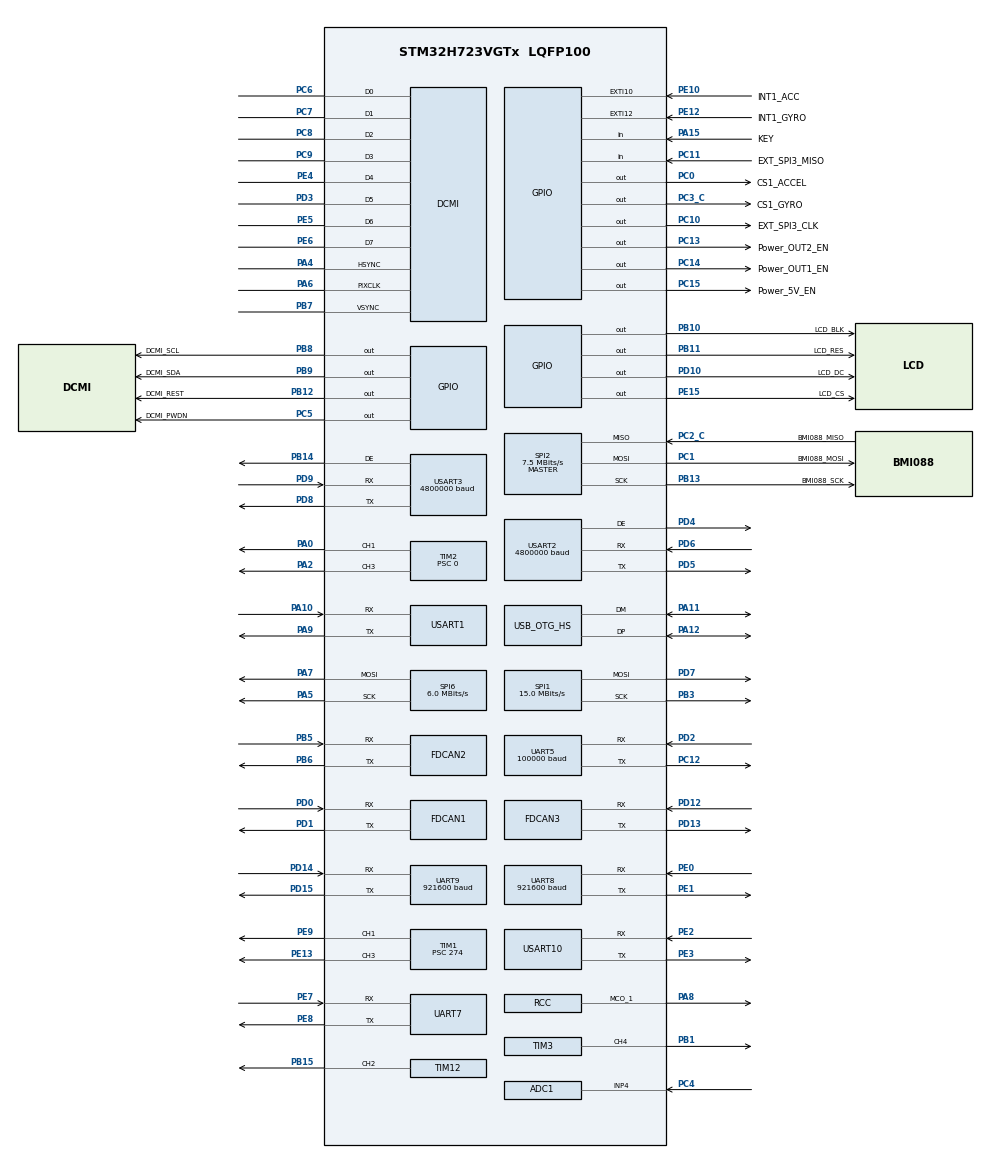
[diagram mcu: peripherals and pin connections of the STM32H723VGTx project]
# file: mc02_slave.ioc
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ADC1.Channel-0\#ChannelRegularConversion=ADC_CHANNEL_4
ADC1.ClockPrescaler=ADC_CLOCK_ASYNC_DIV128
ADC1.ContinuousConvMode=ENABLE
ADC1.ConversionDataManagement=ADC_CONVERSIONDATA_DMA_CIRCULAR
ADC1.NbrOfConversionFlag=1
ADC1.OffsetNumber-0\#ChannelRegularConversion=ADC_OFFSET_NONE
ADC1.OffsetSignedSaturation-0\#ChannelRegularConversion=DISABLE
ADC1.Rank-0\#ChannelRegularConversion=1
ADC1.SamplingTime-0\#ChannelRegularConversion=ADC_SAMPLETIME_64CYCLES_5
ADC1.master=1
Bdma.Request0=SPI6_TX
Bdma.RequestsNb=1
Bdma.SPI6_TX.0.Direction=DMA_MEMORY_TO_PERIPH
Bdma.SPI6_TX.0.EventEnable=DISABLE
Bdma.SPI6_TX.0.Instance=BDMA_Channel0
Bdma.SPI6_TX.0.MemDataAlignment=DMA_MDATAALIGN_BYTE
Bdma.SPI6_TX.0.MemInc=DMA_MINC_ENABLE
Bdma.SPI6_TX.0.Mode=DMA_NORMAL
Bdma.SPI6_TX.0.PeriphDataAlignment=DMA_PDATAALIGN_BYTE
Bdma.SPI6_TX.0.PeriphInc=DMA_PINC_DISABLE
Bdma.SPI6_TX.0.Polarity=HAL_DMAMUX_REQ_GEN_RISING
Bdma.SPI6_TX.0.Priority=DMA_PRIORITY_LOW
Bdma.SPI6_TX.0.RequestNumber=1
Bdma.SPI6_TX.0.SignalID=NONE
Bdma.SPI6_TX.0.SyncEnable=DISABLE
Bdma.SPI6_TX.0.SyncPolarity=HAL_DMAMUX_SYNC_NO_EVENT
Bdma.SPI6_TX.0.SyncRequestNumber=1
Bdma.SPI6_TX.0.SyncSignalID=NONE
CORTEX_M7.AccessPermission_Spec=MPU_REGION_FULL_ACCESS
CORTEX_M7.BaseAddress_Spec=0x24000000
CORTEX_M7.CPU_DCache=Enabled
CORTEX_M7.CPU_ICache=Enabled
CORTEX_M7.DisableExec_Spec=MPU_INSTRUCTION_ACCESS_ENABLE
CORTEX_M7.Enable_S-Cortex_Memory_Protection_Unit_Region1_Settings_S=__NULL
CORTEX_M7.Enable_S-Cortex_Memory_Protection_Unit_Region2_Settings_S=__NULL
CORTEX_M7.IsShareable_Spec=MPU_ACCESS_NOT_SHAREABLE
CORTEX_M7.MPU_Control=MPU_HFNMI_PRIVDEF
CORTEX_M7.Size_Spec=MPU_REGION_SIZE_32KB
CORTEX_M7.SubRegionDisable_Spec=0x00
CORTEX_M7.TypeExtField_Spec=MPU_TEX_LEVEL1
CORTEX_M7.default_mode_Activation=1
DCMI.JPEGMode=DCMI_JPEG_DISABLE
DCMI.PCKPolarity=DCMI_PCKPOLARITY_RISING
DCMI.VSPolarity=DCMI_VSPOLARITY_LOW
Dma.ADC1.13.Direction=DMA_PERIPH_TO_MEMORY
Dma.ADC1.13.EventEnable=DISABLE
Dma.ADC1.13.FIFOMode=DMA_FIFOMODE_DISABLE
Dma.ADC1.13.Instance=DMA2_Stream5
Dma.ADC1.13.MemDataAlignment=DMA_MDATAALIGN_HALFWORD
Dma.ADC1.13.MemInc=DMA_MINC_ENABLE
Dma.ADC1.13.Mode=DMA_CIRCULAR
Dma.ADC1.13.PeriphDataAlignment=DMA_PDATAALIGN_HALFWORD
Dma.ADC1.13.PeriphInc=DMA_PINC_DISABLE
Dma.ADC1.13.Polarity=HAL_DMAMUX_REQ_GEN_RISING
Dma.ADC1.13.Priority=DMA_PRIORITY_LOW
Dma.ADC1.13.RequestNumber=1
Dma.ADC1.13.SignalID=NONE
Dma.ADC1.13.SyncEnable=DISABLE
Dma.ADC1.13.SyncPolarity=HAL_DMAMUX_SYNC_NO_EVENT
Dma.ADC1.13.SyncRequestNumber=1
Dma.ADC1.13.SyncSignalID=NONE
Dma.Request0=USART10_RX
Dma.Request1=USART10_TX
Dma.Request10=USART2_TX
Dma.Request11=USART3_RX
Dma.Request12=USART3_TX
Dma.Request13=ADC1
Dma.Request2=UART7_RX
Dma.Request3=UART7_TX
Dma.Request4=USART1_RX
Dma.Request5=USART1_TX
Dma.Request6=UART5_RX
Dma.Request7=SPI2_RX
Dma.Request8=SPI2_TX
Dma.Request9=USART2_RX
Dma.SPI2_RX.7.Direction=DMA_PERIPH_TO_MEMORY
Dma.SPI2_RX.7.EventEnable=DISABLE
Dma.SPI2_RX.7.FIFOMode=DMA_FIFOMODE_DISABLE
Dma.SPI2_RX.7.Instance=DMA2_Stream0
Dma.SPI2_RX.7.MemDataAlignment=DMA_MDATAALIGN_BYTE
Dma.SPI2_RX.7.MemInc=DMA_MINC_ENABLE
Dma.SPI2_RX.7.Mode=DMA_NORMAL
Dma.SPI2_RX.7.PeriphDataAlignment=DMA_PDATAALIGN_BYTE
Dma.SPI2_RX.7.PeriphInc=DMA_PINC_DISABLE
Dma.SPI2_RX.7.Polarity=HAL_DMAMUX_REQ_GEN_RISING
Dma.SPI2_RX.7.Priority=DMA_PRIORITY_LOW
Dma.SPI2_RX.7.RequestNumber=1
Dma.SPI2_RX.7.SignalID=NONE
Dma.SPI2_RX.7.SyncEnable=DISABLE
Dma.SPI2_RX.7.SyncPolarity=HAL_DMAMUX_SYNC_NO_EVENT
Dma.SPI2_RX.7.SyncRequestNumber=1
Dma.SPI2_RX.7.SyncSignalID=NONE
Dma.SPI2_TX.8.Direction=DMA_MEMORY_TO_PERIPH
Dma.SPI2_TX.8.EventEnable=DISABLE
Dma.SPI2_TX.8.FIFOMode=DMA_FIFOMODE_DISABLE
Dma.SPI2_TX.8.Instance=DMA2_Stream1
Dma.SPI2_TX.8.MemDataAlignment=DMA_MDATAALIGN_BYTE
Dma.SPI2_TX.8.MemInc=DMA_MINC_ENABLE
Dma.SPI2_TX.8.Mode=DMA_NORMAL
Dma.SPI2_TX.8.PeriphDataAlignment=DMA_PDATAALIGN_BYTE
Dma.SPI2_TX.8.PeriphInc=DMA_PINC_DISABLE
Dma.SPI2_TX.8.Polarity=HAL_DMAMUX_REQ_GEN_RISING
Dma.SPI2_TX.8.Priority=DMA_PRIORITY_LOW
Dma.SPI2_TX.8.RequestNumber=1
Dma.SPI2_TX.8.SignalID=NONE
Dma.SPI2_TX.8.SyncEnable=DISABLE
Dma.SPI2_TX.8.SyncPolarity=HAL_DMAMUX_SYNC_NO_EVENT
Dma.SPI2_TX.8.SyncRequestNumber=1
Dma.SPI2_TX.8.SyncSignalID=NONE
Dma.UART5_RX.6.Direction=DMA_PERIPH_TO_MEMORY
Dma.UART5_RX.6.EventEnable=DISABLE
Dma.UART5_RX.6.FIFOMode=DMA_FIFOMODE_DISABLE
Dma.UART5_RX.6.Instance=DMA1_Stream0
Dma.UART5_RX.6.MemDataAlignment=DMA_MDATAALIGN_BYTE
Dma.UART5_RX.6.MemInc=DMA_MINC_ENABLE
Dma.UART5_RX.6.Mode=DMA_CIRCULAR
Dma.UART5_RX.6.PeriphDataAlignment=DMA_PDATAALIGN_BYTE
Dma.UART5_RX.6.PeriphInc=DMA_PINC_DISABLE
Dma.UART5_RX.6.Polarity=HAL_DMAMUX_REQ_GEN_RISING
Dma.UART5_RX.6.Priority=DMA_PRIORITY_HIGH
Dma.UART5_RX.6.RequestNumber=1
Dma.UART5_RX.6.SignalID=NONE
Dma.UART5_RX.6.SyncEnable=DISABLE
Dma.UART5_RX.6.SyncPolarity=HAL_DMAMUX_SYNC_NO_EVENT
Dma.UART5_RX.6.SyncRequestNumber=1
Dma.UART5_RX.6.SyncSignalID=NONE
Dma.UART7_RX.2.Direction=DMA_PERIPH_TO_MEMORY
Dma.UART7_RX.2.EventEnable=DISABLE
Dma.UART7_RX.2.FIFOMode=DMA_FIFOMODE_DISABLE
Dma.UART7_RX.2.Instance=DMA1_Stream3
Dma.UART7_RX.2.MemDataAlignment=DMA_MDATAALIGN_BYTE
Dma.UART7_RX.2.MemInc=DMA_MINC_ENABLE
Dma.UART7_RX.2.Mode=DMA_CIRCULAR
Dma.UART7_RX.2.PeriphDataAlignment=DMA_PDATAALIGN_BYTE
Dma.UART7_RX.2.PeriphInc=DMA_PINC_DISABLE
Dma.UART7_RX.2.Polarity=HAL_DMAMUX_REQ_GEN_RISING
Dma.UART7_RX.2.Priority=DMA_PRIORITY_HIGH
Dma.UART7_RX.2.RequestNumber=1
Dma.UART7_RX.2.SignalID=NONE
Dma.UART7_RX.2.SyncEnable=DISABLE
Dma.UART7_RX.2.SyncPolarity=HAL_DMAMUX_SYNC_NO_EVENT
Dma.UART7_RX.2.SyncRequestNumber=1
Dma.UART7_RX.2.SyncSignalID=NONE
Dma.UART7_TX.3.Direction=DMA_MEMORY_TO_PERIPH
Dma.UART7_TX.3.EventEnable=DISABLE
Dma.UART7_TX.3.FIFOMode=DMA_FIFOMODE_DISABLE
Dma.UART7_TX.3.Instance=DMA1_Stream4
Dma.UART7_TX.3.MemDataAlignment=DMA_MDATAALIGN_BYTE
Dma.UART7_TX.3.MemInc=DMA_MINC_ENABLE
Dma.UART7_TX.3.Mode=DMA_NORMAL
Dma.UART7_TX.3.PeriphDataAlignment=DMA_PDATAALIGN_BYTE
Dma.UART7_TX.3.PeriphInc=DMA_PINC_DISABLE
Dma.UART7_TX.3.Polarity=HAL_DMAMUX_REQ_GEN_RISING
Dma.UART7_TX.3.Priority=DMA_PRIORITY_LOW
Dma.UART7_TX.3.RequestNumber=1
Dma.UART7_TX.3.SignalID=NONE
Dma.UART7_TX.3.SyncEnable=DISABLE
Dma.UART7_TX.3.SyncPolarity=HAL_DMAMUX_SYNC_NO_EVENT
Dma.UART7_TX.3.SyncRequestNumber=1
Dma.UART7_TX.3.SyncSignalID=NONE
Dma.USART10_RX.0.Direction=DMA_PERIPH_TO_MEMORY
Dma.USART10_RX.0.EventEnable=DISABLE
Dma.USART10_RX.0.FIFOMode=DMA_FIFOMODE_DISABLE
Dma.USART10_RX.0.Instance=DMA1_Stream1
Dma.USART10_RX.0.MemDataAlignment=DMA_MDATAALIGN_BYTE
Dma.USART10_RX.0.MemInc=DMA_MINC_ENABLE
Dma.USART10_RX.0.Mode=DMA_CIRCULAR
Dma.USART10_RX.0.PeriphDataAlignment=DMA_PDATAALIGN_BYTE
Dma.USART10_RX.0.PeriphInc=DMA_PINC_DISABLE
Dma.USART10_RX.0.Polarity=HAL_DMAMUX_REQ_GEN_RISING
Dma.USART10_RX.0.Priority=DMA_PRIORITY_HIGH
Dma.USART10_RX.0.RequestNumber=1
Dma.USART10_RX.0.SignalID=NONE
Dma.USART10_RX.0.SyncEnable=DISABLE
Dma.USART10_RX.0.SyncPolarity=HAL_DMAMUX_SYNC_NO_EVENT
Dma.USART10_RX.0.SyncRequestNumber=1
Dma.USART10_RX.0.SyncSignalID=NONE
Dma.USART10_TX.1.Direction=DMA_MEMORY_TO_PERIPH
Dma.USART10_TX.1.EventEnable=DISABLE
Dma.USART10_TX.1.FIFOMode=DMA_FIFOMODE_DISABLE
Dma.USART10_TX.1.Instance=DMA1_Stream2
Dma.USART10_TX.1.MemDataAlignment=DMA_MDATAALIGN_BYTE
Dma.USART10_TX.1.MemInc=DMA_MINC_ENABLE
Dma.USART10_TX.1.Mode=DMA_NORMAL
Dma.USART10_TX.1.PeriphDataAlignment=DMA_PDATAALIGN_BYTE
Dma.USART10_TX.1.PeriphInc=DMA_PINC_DISABLE
Dma.USART10_TX.1.Polarity=HAL_DMAMUX_REQ_GEN_RISING
Dma.USART10_TX.1.Priority=DMA_PRIORITY_HIGH
Dma.USART10_TX.1.RequestNumber=1
Dma.USART10_TX.1.SignalID=NONE
Dma.USART10_TX.1.SyncEnable=DISABLE
Dma.USART10_TX.1.SyncPolarity=HAL_DMAMUX_SYNC_NO_EVENT
Dma.USART10_TX.1.SyncRequestNumber=1
Dma.USART10_TX.1.SyncSignalID=NONE
Dma.USART1_RX.4.Direction=DMA_PERIPH_TO_MEMORY
Dma.USART1_RX.4.EventEnable=DISABLE
Dma.USART1_RX.4.FIFOMode=DMA_FIFOMODE_DISABLE
Dma.USART1_RX.4.Instance=DMA1_Stream5
Dma.USART1_RX.4.MemDataAlignment=DMA_MDATAALIGN_BYTE
Dma.USART1_RX.4.MemInc=DMA_MINC_ENABLE
Dma.USART1_RX.4.Mode=DMA_CIRCULAR
Dma.USART1_RX.4.PeriphDataAlignment=DMA_PDATAALIGN_BYTE
Dma.USART1_RX.4.PeriphInc=DMA_PINC_DISABLE
Dma.USART1_RX.4.Polarity=HAL_DMAMUX_REQ_GEN_RISING
Dma.USART1_RX.4.Priority=DMA_PRIORITY_HIGH
Dma.USART1_RX.4.RequestNumber=1
Dma.USART1_RX.4.SignalID=NONE
Dma.USART1_RX.4.SyncEnable=DISABLE
Dma.USART1_RX.4.SyncPolarity=HAL_DMAMUX_SYNC_NO_EVENT
Dma.USART1_RX.4.SyncRequestNumber=1
Dma.USART1_RX.4.SyncSignalID=NONE
Dma.USART1_TX.5.Direction=DMA_MEMORY_TO_PERIPH
Dma.USART1_TX.5.EventEnable=DISABLE
Dma.USART1_TX.5.FIFOMode=DMA_FIFOMODE_DISABLE
Dma.USART1_TX.5.Instance=DMA1_Stream6
Dma.USART1_TX.5.MemDataAlignment=DMA_MDATAALIGN_BYTE
Dma.USART1_TX.5.MemInc=DMA_MINC_ENABLE
Dma.USART1_TX.5.Mode=DMA_NORMAL
Dma.USART1_TX.5.PeriphDataAlignment=DMA_PDATAALIGN_BYTE
Dma.USART1_TX.5.PeriphInc=DMA_PINC_DISABLE
Dma.USART1_TX.5.Polarity=HAL_DMAMUX_REQ_GEN_RISING
Dma.USART1_TX.5.Priority=DMA_PRIORITY_LOW
Dma.USART1_TX.5.RequestNumber=1
Dma.USART1_TX.5.SignalID=NONE
Dma.USART1_TX.5.SyncEnable=DISABLE
Dma.USART1_TX.5.SyncPolarity=HAL_DMAMUX_SYNC_NO_EVENT
Dma.USART1_TX.5.SyncRequestNumber=1
Dma.USART1_TX.5.SyncSignalID=NONE
Dma.USART2_RX.9.Direction=DMA_PERIPH_TO_MEMORY
Dma.USART2_RX.9.EventEnable=DISABLE
Dma.USART2_RX.9.FIFOMode=DMA_FIFOMODE_DISABLE
Dma.USART2_RX.9.Instance=DMA1_Stream7
Dma.USART2_RX.9.MemDataAlignment=DMA_MDATAALIGN_BYTE
Dma.USART2_RX.9.MemInc=DMA_MINC_ENABLE
Dma.USART2_RX.9.Mode=DMA_CIRCULAR
Dma.USART2_RX.9.PeriphDataAlignment=DMA_PDATAALIGN_BYTE
Dma.USART2_RX.9.PeriphInc=DMA_PINC_DISABLE
Dma.USART2_RX.9.Polarity=HAL_DMAMUX_REQ_GEN_RISING
Dma.USART2_RX.9.Priority=DMA_PRIORITY_HIGH
Dma.USART2_RX.9.RequestNumber=1
Dma.USART2_RX.9.SignalID=NONE
Dma.USART2_RX.9.SyncEnable=DISABLE
Dma.USART2_RX.9.SyncPolarity=HAL_DMAMUX_SYNC_NO_EVENT
Dma.USART2_RX.9.SyncRequestNumber=1
Dma.USART2_RX.9.SyncSignalID=NONE
Dma.USART2_TX.10.Direction=DMA_MEMORY_TO_PERIPH
Dma.USART2_TX.10.EventEnable=DISABLE
Dma.USART2_TX.10.FIFOMode=DMA_FIFOMODE_DISABLE
Dma.USART2_TX.10.Instance=DMA2_Stream2
Dma.USART2_TX.10.MemDataAlignment=DMA_MDATAALIGN_BYTE
Dma.USART2_TX.10.MemInc=DMA_MINC_ENABLE
Dma.USART2_TX.10.Mode=DMA_NORMAL
Dma.USART2_TX.10.PeriphDataAlignment=DMA_PDATAALIGN_BYTE
Dma.USART2_TX.10.PeriphInc=DMA_PINC_DISABLE
Dma.USART2_TX.10.Polarity=HAL_DMAMUX_REQ_GEN_RISING
Dma.USART2_TX.10.Priority=DMA_PRIORITY_LOW
Dma.USART2_TX.10.RequestNumber=1
Dma.USART2_TX.10.SignalID=NONE
Dma.USART2_TX.10.SyncEnable=DISABLE
Dma.USART2_TX.10.SyncPolarity=HAL_DMAMUX_SYNC_NO_EVENT
Dma.USART2_TX.10.SyncRequestNumber=1
Dma.USART2_TX.10.SyncSignalID=NONE
Dma.USART3_RX.11.Direction=DMA_PERIPH_TO_MEMORY
Dma.USART3_RX.11.EventEnable=DISABLE
Dma.USART3_RX.11.FIFOMode=DMA_FIFOMODE_DISABLE
Dma.USART3_RX.11.Instance=DMA2_Stream3
Dma.USART3_RX.11.MemDataAlignment=DMA_MDATAALIGN_BYTE
Dma.USART3_RX.11.MemInc=DMA_MINC_ENABLE
Dma.USART3_RX.11.Mode=DMA_CIRCULAR
Dma.USART3_RX.11.PeriphDataAlignment=DMA_PDATAALIGN_BYTE
Dma.USART3_RX.11.PeriphInc=DMA_PINC_DISABLE
Dma.USART3_RX.11.Polarity=HAL_DMAMUX_REQ_GEN_RISING
Dma.USART3_RX.11.Priority=DMA_PRIORITY_HIGH
Dma.USART3_RX.11.RequestNumber=1
Dma.USART3_RX.11.SignalID=NONE
Dma.USART3_RX.11.SyncEnable=DISABLE
Dma.USART3_RX.11.SyncPolarity=HAL_DMAMUX_SYNC_NO_EVENT
Dma.USART3_RX.11.SyncRequestNumber=1
Dma.USART3_RX.11.SyncSignalID=NONE
Dma.USART3_TX.12.Direction=DMA_MEMORY_TO_PERIPH
Dma.USART3_TX.12.EventEnable=DISABLE
Dma.USART3_TX.12.FIFOMode=DMA_FIFOMODE_DISABLE
Dma.USART3_TX.12.Instance=DMA2_Stream4
Dma.USART3_TX.12.MemDataAlignment=DMA_MDATAALIGN_BYTE
Dma.USART3_TX.12.MemInc=DMA_MINC_ENABLE
Dma.USART3_TX.12.Mode=DMA_NORMAL
Dma.USART3_TX.12.PeriphDataAlignment=DMA_PDATAALIGN_BYTE
Dma.USART3_TX.12.PeriphInc=DMA_PINC_DISABLE
Dma.USART3_TX.12.Polarity=HAL_DMAMUX_REQ_GEN_RISING
Dma.USART3_TX.12.Priority=DMA_PRIORITY_LOW
Dma.USART3_TX.12.RequestNumber=1
Dma.USART3_TX.12.SignalID=NONE
Dma.USART3_TX.12.SyncEnable=DISABLE
Dma.USART3_TX.12.SyncPolarity=HAL_DMAMUX_SYNC_NO_EVENT
Dma.USART3_TX.12.SyncRequestNumber=1
Dma.USART3_TX.12.SyncSignalID=NONE
FDCAN1.AutoRetransmission=DISABLE
FDCAN1.CalculateBaudRateData=5000000
FDCAN1.CalculateBaudRateNominal=1000000
FDCAN1.CalculateTimeBitData=200
FDCAN1.CalculateTimeBitNominal=1000
FDCAN1.CalculateTimeQuantumData=12.5
FDCAN1.CalculateTimeQuantumNominal=62.5
FDCAN1.DataPrescaler=1
FDCAN1.DataTimeSeg1=13
FDCAN1.DataTimeSeg2=2
FDCAN1.FrameFormat=FDCAN_FRAME_FD_BRS
FDCAN1.NominalPrescaler=5
FDCAN1.NominalTimeSeg1=13
FDCAN1.NominalTimeSeg2=2
FDCAN1.RxFifo0ElmtsNbr=32
FDCAN1.RxFifo1ElmtsNbr=0
FDCAN1.StdFiltersNbr=1
FDCAN1.TxFifoQueueElmtsNbr=32
FDCAN2.AutoRetransmission=DISABLE
FDCAN2.CalculateBaudRateData=5000000
FDCAN2.CalculateBaudRateNominal=1000000
FDCAN2.CalculateTimeBitData=200
FDCAN2.CalculateTimeBitNominal=1000
FDCAN2.CalculateTimeQuantumData=12.5
FDCAN2.CalculateTimeQuantumNominal=62.5
FDCAN2.DataPrescaler=1
FDCAN2.DataTimeSeg1=13
FDCAN2.DataTimeSeg2=2
FDCAN2.FrameFormat=FDCAN_FRAME_FD_BRS
FDCAN2.MessageRAMOffset=0x200
FDCAN2.NominalPrescaler=5
FDCAN2.NominalTimeSeg1=13
FDCAN2.NominalTimeSeg2=2
FDCAN2.RxFifo0ElmtsNbr=32
FDCAN2.RxFifo1ElmtsNbr=0
FDCAN2.StdFiltersNbr=1
FDCAN2.TxFifoQueueElmtsNbr=32
FDCAN3.AutoRetransmission=DISABLE
FDCAN3.CalculateBaudRateData=5000000
FDCAN3.CalculateBaudRateNominal=1000000
FDCAN3.CalculateTimeBitData=200
FDCAN3.CalculateTimeBitNominal=1000
FDCAN3.CalculateTimeQuantumData=12.5
FDCAN3.CalculateTimeQuantumNominal=62.5
FDCAN3.DataPrescaler=1
FDCAN3.DataTimeSeg1=13
FDCAN3.DataTimeSeg2=2
FDCAN3.FrameFormat=FDCAN_FRAME_FD_BRS
FDCAN3.MessageRAMOffset=0x400
FDCAN3.NominalPrescaler=5
FDCAN3.NominalTimeSeg1=13
FDCAN3.NominalTimeSeg2=2
FDCAN3.RxFifo0ElmtsNbr=32
FDCAN3.StdFiltersNbr=1
FDCAN3.TxFifoQueueElmtsNbr=32
Mcu.Family=STM32H7
Mcu.Name=STM32H723VGTx
Mcu.Package=LQFP100
NVIC.BDMA_Channel0_IRQn=true\:4\:0\:false\:false\:true\:false\:true\:true
NVIC.DMA1_Stream0_IRQn=true\:3\:0\:true\:false\:true\:false\:true\:true
NVIC.DMA1_Stream1_IRQn=true\:3\:0\:true\:false\:true\:false\:true\:true
NVIC.DMA1_Stream2_IRQn=true\:3\:0\:true\:false\:true\:false\:true\:true
NVIC.DMA1_Stream3_IRQn=true\:3\:0\:true\:false\:true\:false\:true\:true
NVIC.DMA1_Stream4_IRQn=true\:3\:0\:true\:false\:true\:false\:true\:true
NVIC.DMA1_Stream5_IRQn=true\:3\:0\:true\:false\:true\:false\:true\:true
NVIC.DMA1_Stream6_IRQn=true\:3\:0\:true\:false\:true\:false\:true\:true
NVIC.DMA1_Stream7_IRQn=true\:3\:0\:true\:false\:true\:false\:true\:true
NVIC.DMA2_Stream0_IRQn=true\:3\:0\:false\:false\:true\:false\:true\:true
NVIC.DMA2_Stream1_IRQn=true\:3\:0\:false\:false\:true\:false\:true\:true
NVIC.DMA2_Stream2_IRQn=true\:3\:0\:true\:false\:true\:false\:true\:true
NVIC.DMA2_Stream3_IRQn=true\:3\:0\:true\:false\:true\:false\:true\:true
NVIC.DMA2_Stream4_IRQn=true\:3\:0\:true\:false\:true\:false\:true\:true
NVIC.DMA2_Stream5_IRQn=true\:5\:0\:false\:false\:true\:false\:true\:true
NVIC.EXTI15_10_IRQn=true\:4\:0\:false\:false\:false\:true\:true\:true
NVIC.FDCAN1_IT0_IRQn=true\:1\:0\:true\:false\:true\:true\:true\:true
NVIC.FDCAN1_IT1_IRQn=true\:1\:0\:true\:false\:true\:true\:true\:true
NVIC.FDCAN2_IT0_IRQn=true\:1\:0\:true\:false\:true\:true\:true\:true
NVIC.FDCAN2_IT1_IRQn=true\:1\:0\:true\:false\:true\:true\:true\:true
NVIC.FDCAN3_IT0_IRQn=true\:1\:0\:true\:false\:true\:true\:true\:true
NVIC.FDCAN3_IT1_IRQn=true\:1\:0\:true\:false\:true\:true\:true\:true
NVIC.OTG_HS_IRQn=true\:2\:0\:false\:false\:true\:true\:true\:true
NVIC.PriorityGroup=NVIC_PRIORITYGROUP_4
NVIC.SPI2_IRQn=true\:4\:0\:false\:false\:true\:true\:true\:true
NVIC.SPI6_IRQn=true\:4\:0\:true\:false\:true\:false\:true\:true
NVIC.UART5_IRQn=true\:3\:0\:true\:false\:true\:true\:true\:true
NVIC.UART7_IRQn=true\:3\:0\:true\:false\:true\:true\:true\:true
NVIC.USART10_IRQn=true\:3\:0\:true\:false\:true\:true\:true\:true
NVIC.USART1_IRQn=true\:3\:0\:true\:false\:true\:true\:true\:true
NVIC.USART2_IRQn=true\:3\:0\:true\:false\:true\:true\:true\:true
NVIC.USART3_IRQn=true\:3\:0\:true\:false\:true\:true\:true\:true
PA0.Signal=S_TIM2_CH1_ETR
PA1.Signal=OCTOSPIM_P1_IO3
PA10.Mode=Asynchronous
PA10.Signal=USART1_RX
PA11.Mode=Device_Only_FS
PA11.Signal=USB_OTG_HS_DM
PA12.Mode=Device_Only_FS
PA12.Signal=USB_OTG_HS_DP
PA13(JTMS/SWDIO).Mode=Serial_Wire
PA13(JTMS/SWDIO).Signal=DEBUG_JTMS-SWDIO
PA14(JTCK/SWCLK).Mode=Serial_Wire
PA14(JTCK/SWCLK).Signal=DEBUG_JTCK-SWCLK
PA15(JTDI).GPIO_Label=KEY
PA15(JTDI).GPIO_PuPd=GPIO_PULLUP
PA15(JTDI).Signal=GPIO_Input
PA2.Signal=S_TIM2_CH3
PA3.Signal=OCTOSPIM_P1_IO2
PA4.GPIO_Speed=GPIO_SPEED_FREQ_VERY_HIGH
PA4.Mode=Slave_8_bits_External_Synchro
PA4.Signal=DCMI_HSYNC
PA5.Mode=TX_Only_Simplex_Unidirect_Master
PA5.Signal=SPI6_SCK
PA6.GPIO_Speed=GPIO_SPEED_FREQ_VERY_HIGH
PA6.Mode=Slave_8_bits_External_Synchro
PA6.Signal=DCMI_PIXCLK
PA7.Mode=TX_Only_Simplex_Unidirect_Master
PA7.Signal=SPI6_MOSI
PA8.Mode=Clock-out-1
PA8.Signal=RCC_MCO_1
PA9.Mode=Asynchronous
PA9.Signal=USART1_TX
PB0.Signal=OCTOSPIM_P1_IO1
PB1.Signal=S_TIM3_CH4
PB10.GPIO_Label=LCD_BLK
PB10.Signal=GPIO_Output
PB11.GPIO_Label=LCD_RES
PB11.Signal=GPIO_Output
PB12.GPIO_Label=DCMI_REST
PB12.GPIO_PuPd=GPIO_PULLUP
PB12.GPIO_Speed=GPIO_SPEED_FREQ_VERY_HIGH
PB12.PinState=GPIO_PIN_SET
PB12.Signal=GPIO_Output
PB13.GPIO_Label=BMI088_SCK
PB13.GPIO_PuPd=GPIO_NOPULL
PB13.GPIO_Speed=GPIO_SPEED_FREQ_VERY_HIGH
PB13.Mode=Full_Duplex_Master
PB13.Signal=SPI2_SCK
PB14.Mode=Hardware Flow Control (RS485)
PB14.Signal=USART3_DE
PB15.Signal=S_TIM12_CH2
PB2.Signal=OCTOSPIM_P1_CLK
PB3(JTDO/TRACESWO).GPIO_Speed=GPIO_SPEED_FREQ_VERY_HIGH
PB3(JTDO/TRACESWO).Mode=TX_Only_Simplex_Unidirect_Master
PB3(JTDO/TRACESWO).Signal=SPI1_SCK
PB5.GPIO_Speed=GPIO_SPEED_FREQ_VERY_HIGH
PB5.Mode=FDCAN_Activate
PB5.Signal=FDCAN2_RX
PB6.GPIO_Speed=GPIO_SPEED_FREQ_VERY_HIGH
PB6.Mode=FDCAN_Activate
PB6.Signal=FDCAN2_TX
PB7.GPIO_Speed=GPIO_SPEED_FREQ_VERY_HIGH
PB7.Mode=Slave_8_bits_External_Synchro
PB7.Signal=DCMI_VSYNC
PB8.GPIO_Label=DCMI_SCL
PB8.GPIO_ModeDefaultOutputPP=GPIO_MODE_OUTPUT_OD
PB8.GPIO_PuPd=GPIO_PULLUP
PB8.Signal=GPIO_Output
PB9.GPIO_Label=DCMI_SDA
PB9.GPIO_ModeDefaultOutputPP=GPIO_MODE_OUTPUT_OD
PB9.GPIO_PuPd=GPIO_PULLUP
PB9.Signal=GPIO_Output
PC0.GPIO_Label=CS1_ACCEL
PC0.GPIO_PuPd=GPIO_PULLUP
PC0.GPIO_Speed=GPIO_SPEED_FREQ_VERY_HIGH
PC0.PinState=GPIO_PIN_SET
PC0.Signal=GPIO_Output
PC1.GPIO_Label=BMI088_MOSI
PC1.GPIO_Speed=GPIO_SPEED_FREQ_VERY_HIGH
PC1.Mode=Full_Duplex_Master
PC1.Signal=SPI2_MOSI
PC10.GPIO_Label=EXT_SPI3_CLK
PC10.Signal=GPIO_Output
PC11.GPIO_Label=EXT_SPI3_MISO
PC11.Signal=GPIO_Input
PC12.Mode=Asynchronous
PC12.Signal=UART5_TX
PC13.GPIO_Label=Power_OUT2_EN
PC13.PinState=GPIO_PIN_RESET
PC13.Signal=GPIO_Output
PC14-OSC32_IN.GPIO_Label=Power_OUT1_EN
PC14-OSC32_IN.PinState=GPIO_PIN_RESET
PC14-OSC32_IN.Signal=GPIO_Output
PC15-OSC32_OUT.GPIO_Label=Power_5V_EN
PC15-OSC32_OUT.GPIO_ModeDefaultOutputPP=GPIO_MODE_OUTPUT_PP
PC15-OSC32_OUT.GPIO_PuPd=GPIO_PULLUP
PC15-OSC32_OUT.PinState=GPIO_PIN_SET
PC15-OSC32_OUT.Signal=GPIO_Output
PC2_C.GPIO_Label=BMI088_MISO
PC2_C.GPIO_Speed=GPIO_SPEED_FREQ_VERY_HIGH
PC2_C.Mode=Full_Duplex_Master
PC2_C.Signal=SPI2_MISO
PC3_C.GPIO_Label=CS1_GYRO
PC3_C.GPIO_PuPd=GPIO_PULLUP
PC3_C.GPIO_Speed=GPIO_SPEED_FREQ_VERY_HIGH
PC3_C.PinState=GPIO_PIN_SET
PC3_C.Signal=GPIO_Output
PC4.Signal=ADCx_INP4
PC5.GPIO_Label=DCMI_PWDN
PC5.GPIO_PuPd=GPIO_PULLDOWN
PC5.GPIO_Speed=GPIO_SPEED_FREQ_VERY_HIGH
PC5.PinState=GPIO_PIN_SET
PC5.Signal=GPIO_Output
PC6.GPIO_Speed=GPIO_SPEED_FREQ_VERY_HIGH
PC6.Mode=Slave_8_bits_External_Synchro
PC6.Signal=DCMI_D0
PC7.GPIO_Speed=GPIO_SPEED_FREQ_VERY_HIGH
PC7.Mode=Slave_8_bits_External_Synchro
PC7.Signal=DCMI_D1
PC8.GPIO_Speed=GPIO_SPEED_FREQ_VERY_HIGH
PC8.Mode=Slave_8_bits_External_Synchro
PC8.Signal=DCMI_D2
PC9.GPIO_Speed=GPIO_SPEED_FREQ_VERY_HIGH
PC9.Mode=Slave_8_bits_External_Synchro
PC9.Signal=DCMI_D3
PD0.GPIO_Speed=GPIO_SPEED_FREQ_VERY_HIGH
PD0.Mode=FDCAN_Activate
PD0.Signal=FDCAN1_RX
PD1.GPIO_Speed=GPIO_SPEED_FREQ_VERY_HIGH
PD1.Mode=FDCAN_Activate
PD1.Signal=FDCAN1_TX
PD10.GPIO_Label=LCD_DC
PD10.Signal=GPIO_Output
PD11.Signal=OCTOSPIM_P1_IO0
PD12.GPIO_Speed=GPIO_SPEED_FREQ_VERY_HIGH
PD12.Mode=FDCAN_Activate
PD12.Signal=FDCAN3_RX
PD13.GPIO_Speed=GPIO_SPEED_FREQ_VERY_HIGH
PD13.Mode=FDCAN_Activate
PD13.Signal=FDCAN3_TX
PD14.Mode=Asynchronous
PD14.Signal=UART9_RX
PD15.Mode=Asynchronous
PD15.Signal=UART9_TX
PD2.GPIO_Speed=GPIO_SPEED_FREQ_VERY_HIGH
PD2.Mode=Asynchronous
PD2.Signal=UART5_RX
PD3.GPIO_Speed=GPIO_SPEED_FREQ_VERY_HIGH
PD3.Mode=Slave_8_bits_External_Synchro
PD3.Signal=DCMI_D5
PD4.Mode=Hardware Flow Control (RS485)
PD4.Signal=USART2_DE
PD5.Mode=Asynchronous
PD5.Signal=USART2_TX
PD6.Mode=Asynchronous
PD6.Signal=USART2_RX
PD7.GPIO_Speed=GPIO_SPEED_FREQ_VERY_HIGH
PD7.Mode=TX_Only_Simplex_Unidirect_Master
PD7.Signal=SPI1_MOSI
PD8.Mode=Asynchronous
PD8.Signal=USART3_TX
PD9.Mode=Asynchronous
PD9.Signal=USART3_RX
PE0.Mode=Asynchronous
PE0.Signal=UART8_RX
PE1.Mode=Asynchronous
PE1.Signal=UART8_TX
PE10.GPIO_Label=INT1_ACC
PE10.Signal=GPXTI10
PE11.Signal=OCTOSPIM_P1_NCS
PE12.GPIO_Label=INT1_GYRO
PE12.Signal=GPXTI12
PE13.Signal=S_TIM1_CH3
PE14.Signal=SPI4_MOSI
PE15.GPIO_Label=LCD_CS
PE15.Signal=GPIO_Output
PE2.Mode=Asynchronous
PE2.Signal=USART10_RX
PE3.Mode=Asynchronous
PE3.Signal=USART10_TX
PE4.GPIO_Speed=GPIO_SPEED_FREQ_VERY_HIGH
PE4.Mode=Slave_8_bits_External_Synchro
PE4.Signal=DCMI_D4
PE5.GPIO_Speed=GPIO_SPEED_FREQ_VERY_HIGH
PE5.Mode=Slave_8_bits_External_Synchro
PE5.Signal=DCMI_D6
PE6.GPIO_Speed=GPIO_SPEED_FREQ_VERY_HIGH
PE6.Mode=Slave_8_bits_External_Synchro
PE6.Signal=DCMI_D7
PE7.GPIO_Speed=GPIO_SPEED_FREQ_VERY_HIGH
PE7.Mode=Asynchronous
PE7.Signal=UART7_RX
PE8.GPIO_PuPd=GPIO_NOPULL
PE8.GPIO_Speed=GPIO_SPEED_FREQ_VERY_HIGH
PE8.Mode=Asynchronous
PE8.Signal=UART7_TX
PE9.Signal=S_TIM1_CH1
PH0-OSC_IN.Mode=HSE-External-Oscillator
PH0-OSC_IN.Signal=RCC_OSC_IN
PH1-OSC_OUT.Mode=HSE-External-Oscillator
PH1-OSC_OUT.Signal=RCC_OSC_OUT
ProjectManager.HeapSize=0x2000
ProjectManager.StackSize=0x2000
ProjectManager.TargetToolchain=CMake
RCC.ADCFreq_Value=120000000
RCC.APB1Freq_Value=137500000
RCC.APB2Freq_Value=137500000
RCC.APB3Freq_Value=137500000
RCC.APB4Freq_Value=137500000
RCC.CortexFreq_Value=550000000
RCC.D1PPRE=RCC_APB3_DIV2
RCC.D2PPRE1=RCC_APB1_DIV2
RCC.D2PPRE2=RCC_APB2_DIV2
RCC.D3PPRE=RCC_APB4_DIV2
RCC.DIVM1=3
RCC.DIVM2=2
RCC.DIVM3=2
RCC.DIVN1=68
RCC.DIVN2=20
RCC.DIVN3=16
RCC.DIVP1=1
RCC.DIVQ1=3
RCC.DIVQ2=3
RCC.DIVQ3=4
RCC.EnbaleCSS=false
RCC.FDCANCLockSelection=RCC_FDCANCLKSOURCE_PLL2
RCC.HCLKFreq_Value=275000000
RCC.HPRE=RCC_HCLK_DIV2
RCC.HSE_VALUE=24000000
RCC.PLL1_VCO_SEL-AdvancedSettings=RCC_PLL1VCOMEDIUM
RCC.PLL2FRACN=0
RCC.PLL2_VCI_Range-AdvancedSettings=RCC_PLL2VCIRANGE_3
RCC.PLL2_VCO_SEL-AdvancedSettings=RCC_PLL2VCOMEDIUM
RCC.PLL3FRACN=0
RCC.PLL3_VCI_Range-AdvancedSettings=RCC_PLL3VCIRANGE_3
RCC.PLL3_VCO_SEL-AdvancedSettings=RCC_PLL3VCOMEDIUM
RCC.PLLFRACN=6144
RCC.PLLSourceVirtual=RCC_PLLSOURCE_HSE
RCC.RCC_MCO1Source=RCC_MCO1SOURCE_HSE
RCC.SPI123CLockSelection=RCC_SPI123CLKSOURCE_PLL2
RCC.SPI6CLockSelection=RCC_SPI6CLKSOURCE_HSE
RCC.SYSCLKFreq_VALUE=550000000
RCC.SYSCLKSource=RCC_SYSCLKSOURCE_PLLCLK
RCC.Spi45ClockSelection=RCC_SPI45CLKSOURCE_HSE
RCC.USART16CLockSelection=RCC_USART16910CLKSOURCE_PLL3
RCC.USART234578CLockSelection=RCC_USART234578CLKSOURCE_PLL3
RCC.USBCLockSelection=RCC_USBCLKSOURCE_PLL3
RCC.USBFreq_Value=48000000
SH.ADCx_INP4.0=ADC1_INP4,IN4-Single-Ended
SH.S_TIM12_CH2.0=TIM12_CH2,PWM Generation2 CH2
SH.S_TIM1_CH1.0=TIM1_CH1,PWM Generation1 CH1
SH.S_TIM1_CH3.0=TIM1_CH3,PWM Generation3 CH3
SH.S_TIM2_CH1_ETR.0=TIM2_CH1,PWM Generation1 CH1
SH.S_TIM2_CH3.0=TIM2_CH3,PWM Generation3 CH3
SH.S_TIM3_CH4.0=TIM3_CH4,PWM Generation4 CH4
SPI1.BaudRatePrescaler=SPI_BAUDRATEPRESCALER_8
SPI1.CLKPolarity=SPI_POLARITY_HIGH
SPI1.CalculateBaudRate=15.0 MBits/s
SPI1.DataSize=SPI_DATASIZE_8BIT
SPI1.Direction=SPI_DIRECTION_2LINES_TXONLY
SPI1.Mode=SPI_MODE_MASTER
SPI1.VirtualType=VM_MASTER
SPI2.BaudRatePrescaler=SPI_BAUDRATEPRESCALER_16
SPI2.CLKPhase=SPI_PHASE_2EDGE
SPI2.CLKPolarity=SPI_POLARITY_HIGH
SPI2.CalculateBaudRate=7.5 MBits/s
SPI2.DataSize=SPI_DATASIZE_8BIT
SPI2.Direction=SPI_DIRECTION_2LINES
SPI2.Mode=SPI_MODE_MASTER
SPI2.VirtualType=VM_MASTER
SPI6.BaudRatePrescaler=SPI_BAUDRATEPRESCALER_4
SPI6.CLKPhase=SPI_PHASE_2EDGE
SPI6.CalculateBaudRate=6.0 MBits/s
SPI6.DataSize=SPI_DATASIZE_8BIT
SPI6.Direction=SPI_DIRECTION_2LINES_TXONLY
SPI6.Mode=SPI_MODE_MASTER
SPI6.VirtualType=VM_MASTER
TIM1.AutoReloadPreload=TIM_AUTORELOAD_PRELOAD_ENABLE
TIM1.Channel-PWM\ Generation1\ CH1=TIM_CHANNEL_1
TIM1.Channel-PWM\ Generation3\ CH3=TIM_CHANNEL_3
TIM1.Period=19999
TIM1.Prescaler=274
TIM12.AutoReloadPreload=TIM_AUTORELOAD_PRELOAD_ENABLE
TIM12.Channel-PWM\ Generation2\ CH2=TIM_CHANNEL_2
TIM12.Period=249
TIM12.Prescaler=274
TIM12.Pulse-PWM\ Generation2\ CH2=125
TIM2.AutoReloadPreload=TIM_AUTORELOAD_PRELOAD_ENABLE
TIM2.Channel-PWM\ Generation1\ CH1=TIM_CHANNEL_1
TIM2.Channel-PWM\ Generation3\ CH3=TIM_CHANNEL_3
TIM2.Period=5499999
TIM2.Prescaler=0
TIM23.AutoReloadPreload=TIM_AUTORELOAD_PRELOAD_DISABLE
TIM23.Period=1073741823
TIM23.Prescaler=274
TIM3.AutoReloadPreload=TIM_AUTORELOAD_PRELOAD_ENABLE
TIM3.Channel-PWM\ Generation4\ CH4=TIM_CHANNEL_4
TIM3.Period=65535
TIM3.Prescaler=1
TIM5.AutoReloadPreload=TIM_AUTORELOAD_PRELOAD_DISABLE
TIM5.Period=4294967295
TIM5.Prescaler=0
UART5.BaudRate=100000
UART5.FIFOMode=FIFOMODE_ENABLE
UART5.Mode=MODE_RX
UART5.Parity=PARITY_EVEN
UART5.StopBits=UART_STOPBITS_1
UART5.WordLength=WORDLENGTH_9B
UART7.FIFOMode=FIFOMODE_ENABLE
UART8.BaudRate=921600
UART8.FIFOMode=FIFOMODE_ENABLE
UART9.BaudRate=921600
UART9.FIFOMode=FIFOMODE_ENABLE
USART1.VirtualMode-Asynchronous=VM_ASYNC
USART10.VirtualMode=VM_ASYNC
USART2.BaudRate=4800000
USART2.OverSampling=UART_OVERSAMPLING_8
USART2.UART_DEAssertionTime=8
USART2.UART_DEDeassertionTime=8
USART2.VirtualMode-Asynchronous=VM_ASYNC
USART2.VirtualMode-Hardware\ Flow\ Control\ (RS485)=VM_ASYNC
USART3.BaudRate=4800000
USART3.OverSampling=UART_OVERSAMPLING_8
USART3.UART_DEAssertionTime=8
USART3.UART_DEDeassertionTime=8
USART3.VirtualMode-Asynchronous=VM_ASYNC
USART3.VirtualMode-Hardware\ Flow\ Control\ (RS485)=VM_ASYNC
USB_OTG_HS.VirtualMode-Device_Only_FS=Device_Only_FS
USB_OTG_HS.dma_enable-Device_Only_FS=DISABLE
VP_MEMORYMAP_VS_MEMORYMAP.Mode=CurAppReg
VP_TIM23_VS_ClockSourceINT.Mode=Internal
VP_TIM5_VS_ClockSourceINT.Mode=Internal
board=custom

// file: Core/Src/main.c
/* USER CODE BEGIN Header */
/**
  ******************************************************************************
  * @file           : main.c
  * @brief          : Main program body
  ******************************************************************************
  * @attention
  *
  * Copyright (c) 2025 STMicroelectronics.
  * All rights reserved.
  *
  * This software is licensed under terms that can be found in the LICENSE file
  * in the root directory of this software component.
  * If no LICENSE file comes with this software, it is provided AS-IS.
  *
  ******************************************************************************
  */
/* USER CODE END Header */
#include "main.h"
#include "adc.h"
#include "bdma.h"
#include "dcmi.h"
#include "dma.h"
#include "fdcan.h"
#include "spi.h"
#include "tim.h"
#include "usart.h"
#include "usb_otg.h"
#include "gpio.h"

void SystemClock_Config(void);
void PeriphCommonClock_Config(void);
static void MPU_Config(void);

int main(void)
{

  /* MPU Configuration--------------------------------------------------------*/
  MPU_Config();

  /* Enable the CPU Cache */

  /* Enable I-Cache---------------------------------------------------------*/
  SCB_EnableICache();

  /* Enable D-Cache---------------------------------------------------------*/
  SCB_EnableDCache();

  /* MCU Configuration--------------------------------------------------------*/

  /* Reset of all peripherals, Initializes the Flash interface and the Systick. */
  HAL_Init();

  /* Configure the system clock */
  SystemClock_Config();

  /* Configure the peripherals common clocks */
  PeriphCommonClock_Config();

  /* Initialize all configured peripherals */
  MX_GPIO_Init();
  MX_DMA_Init();
  MX_BDMA_Init();
  MX_FDCAN1_Init();
  MX_USART10_UART_Init();
  MX_UART7_Init();
  MX_USART1_UART_Init();
  MX_FDCAN2_Init();
  MX_FDCAN3_Init();
  MX_SPI6_Init();
  MX_SPI2_Init();
  MX_UART5_Init();
  MX_TIM1_Init();
  MX_TIM2_Init();
  MX_TIM3_Init();
  MX_TIM12_Init();
  MX_TIM5_Init();
  MX_DCMI_Init();
  MX_SPI1_Init();
  MX_UART8_Init();
  MX_UART9_Init();
  MX_USART2_UART_Init();
  MX_USART3_UART_Init();
  MX_USB_OTG_HS_PCD_Init();
  MX_ADC1_Init();
  MX_TIM23_Init();

  /* Infinite loop */
  while (1)
  {

  }
}

void SystemClock_Config(void)
{
  RCC_OscInitTypeDef RCC_OscInitStruct = {0};
  RCC_ClkInitTypeDef RCC_ClkInitStruct = {0};

  /** Supply configuration update enable
  */
  HAL_PWREx_ConfigSupply(PWR_LDO_SUPPLY);

  /** Configure the main internal regulator output voltage
  */
  __HAL_PWR_VOLTAGESCALING_CONFIG(PWR_REGULATOR_VOLTAGE_SCALE0);

  while(!__HAL_PWR_GET_FLAG(PWR_FLAG_VOSRDY)) {}

  /** Initializes the RCC Oscillators according to the specified parameters
  * in the RCC_OscInitTypeDef structure.
  */
  RCC_OscInitStruct.OscillatorType = RCC_OSCILLATORTYPE_HSE;
  RCC_OscInitStruct.HSEState = RCC_HSE_ON;
  RCC_OscInitStruct.PLL.PLLState = RCC_PLL_ON;
  RCC_OscInitStruct.PLL.PLLSource = RCC_PLLSOURCE_HSE;
  RCC_OscInitStruct.PLL.PLLM = 3;
  RCC_OscInitStruct.PLL.PLLN = 68;
  RCC_OscInitStruct.PLL.PLLP = 1;
  RCC_OscInitStruct.PLL.PLLQ = 3;
  RCC_OscInitStruct.PLL.PLLR = 2;
  RCC_OscInitStruct.PLL.PLLRGE = RCC_PLL1VCIRANGE_3;
  RCC_OscInitStruct.PLL.PLLVCOSEL = RCC_PLL1VCOWIDE;
  RCC_OscInitStruct.PLL.PLLFRACN = 6144;
  if (HAL_RCC_OscConfig(&RCC_OscInitStruct) != HAL_OK)
  {
    Error_Handler();
  }

  /** Initializes the CPU, AHB and APB buses clocks
  */
  RCC_ClkInitStruct.ClockType = RCC_CLOCKTYPE_HCLK|RCC_CLOCKTYPE_SYSCLK
                              |RCC_CLOCKTYPE_PCLK1|RCC_CLOCKTYPE_PCLK2
                              |RCC_CLOCKTYPE_D3PCLK1|RCC_CLOCKTYPE_D1PCLK1;
  RCC_ClkInitStruct.SYSCLKSource = RCC_SYSCLKSOURCE_PLLCLK;
  RCC_ClkInitStruct.SYSCLKDivider = RCC_SYSCLK_DIV1;
  RCC_ClkInitStruct.AHBCLKDivider = RCC_HCLK_DIV2;
  RCC_ClkInitStruct.APB3CLKDivider = RCC_APB3_DIV2;
  RCC_ClkInitStruct.APB1CLKDivider = RCC_APB1_DIV2;
  RCC_ClkInitStruct.APB2CLKDivider = RCC_APB2_DIV2;
  RCC_ClkInitStruct.APB4CLKDivider = RCC_APB4_DIV2;

  if (HAL_RCC_ClockConfig(&RCC_ClkInitStruct, FLASH_LATENCY_3) != HAL_OK)
  {
    Error_Handler();
  }
  HAL_RCC_MCOConfig(RCC_MCO1, RCC_MCO1SOURCE_HSE, RCC_MCODIV_1);
}

void PeriphCommonClock_Config(void)
{
  RCC_PeriphCLKInitTypeDef PeriphClkInitStruct = {0};

  /** Initializes the peripherals clock
  */
  PeriphClkInitStruct.PeriphClockSelection = RCC_PERIPHCLK_USB|RCC_PERIPHCLK_ADC
                              |RCC_PERIPHCLK_SPI2|RCC_PERIPHCLK_SPI1
                              |RCC_PERIPHCLK_UART5|RCC_PERIPHCLK_UART8
                              |RCC_PERIPHCLK_FDCAN|RCC_PERIPHCLK_USART1
                              |RCC_PERIPHCLK_USART10|RCC_PERIPHCLK_UART9
                              |RCC_PERIPHCLK_UART7|RCC_PERIPHCLK_USART2
                              |RCC_PERIPHCLK_USART3;
  PeriphClkInitStruct.PLL2.PLL2M = 2;
  PeriphClkInitStruct.PLL2.PLL2N = 20;
  PeriphClkInitStruct.PLL2.PLL2P = 2;
  PeriphClkInitStruct.PLL2.PLL2Q = 3;
  PeriphClkInitStruct.PLL2.PLL2R = 2;
  PeriphClkInitStruct.PLL2.PLL2RGE = RCC_PLL2VCIRANGE_3;
  PeriphClkInitStruct.PLL2.PLL2VCOSEL = RCC_PLL2VCOWIDE;
  PeriphClkInitStruct.PLL2.PLL2FRACN = 0;
  PeriphClkInitStruct.PLL3.PLL3M = 2;
  PeriphClkInitStruct.PLL3.PLL3N = 16;
  PeriphClkInitStruct.PLL3.PLL3P = 2;
  PeriphClkInitStruct.PLL3.PLL3Q = 4;
  PeriphClkInitStruct.PLL3.PLL3R = 2;
  PeriphClkInitStruct.PLL3.PLL3RGE = RCC_PLL3VCIRANGE_3;
  PeriphClkInitStruct.PLL3.PLL3VCOSEL = RCC_PLL3VCOWIDE;
  PeriphClkInitStruct.PLL3.PLL3FRACN = 0;
  PeriphClkInitStruct.Spi123ClockSelection = RCC_SPI123CLKSOURCE_PLL2;
  PeriphClkInitStruct.FdcanClockSelection = RCC_FDCANCLKSOURCE_PLL2;
  PeriphClkInitStruct.Usart234578ClockSelection = RCC_USART234578CLKSOURCE_PLL3;
  PeriphClkInitStruct.Usart16ClockSelection = RCC_USART16910CLKSOURCE_PLL3;
  PeriphClkInitStruct.UsbClockSelection = RCC_USBCLKSOURCE_PLL3;
  PeriphClkInitStruct.AdcClockSelection = RCC_ADCCLKSOURCE_PLL2;
  if (HAL_RCCEx_PeriphCLKConfig(&PeriphClkInitStruct) != HAL_OK)
  {
    Error_Handler();
  }
}

/* USER CODE BEGIN 4 */
// libhcs: see main.h. MPU_Config() is file-local by CubeMX's ownprototype;
// this wrapper is the external entry point app.cpp calls.
void libhcs_mpu_config(void) { MPU_Config(); }
/* USER CODE END 4 */

 /* MPU Configuration */

void MPU_Config(void)
{
  MPU_Region_InitTypeDef MPU_InitStruct = {0};

  /* Disables the MPU */
  HAL_MPU_Disable();

  /** Initializes and configures the Region and the memory to be protected
  */
  MPU_InitStruct.Enable = MPU_REGION_ENABLE;
  MPU_InitStruct.Number = MPU_REGION_NUMBER0;
  MPU_InitStruct.BaseAddress = 0x24000000;
  MPU_InitStruct.Size = MPU_REGION_SIZE_32KB;
  MPU_InitStruct.SubRegionDisable = 0x00;
  MPU_InitStruct.TypeExtField = MPU_TEX_LEVEL1;
  MPU_InitStruct.AccessPermission = MPU_REGION_FULL_ACCESS;
  MPU_InitStruct.DisableExec = MPU_INSTRUCTION_ACCESS_ENABLE;
  MPU_InitStruct.IsShareable = MPU_ACCESS_NOT_SHAREABLE;
  MPU_InitStruct.IsCacheable = MPU_ACCESS_NOT_CACHEABLE;
  MPU_InitStruct.IsBufferable = MPU_ACCESS_NOT_BUFFERABLE;

  HAL_MPU_ConfigRegion(&MPU_InitStruct);
  /* Enables the MPU */
  HAL_MPU_Enable(MPU_HFNMI_PRIVDEF);

}

void Error_Handler(void)
{
  __disable_irq();
  while (1)
  {
  }
}
